# XMC1100 register map
Vendor: Infineon; File version: 1.2.2 (Reference Manual v1.2)
CPU: CM0 r0p0, little endian, no MPU, no FPU, 2 interrupt priority bits
Registers are 32-bit, read-write, reset 0x0 unless marked. A register's access mark holds for its fields unless they carry their own. Offsets are from the block's base; [hi:lo] are bit positions; {n}, {i} and the like mark numbered series.

## SCU_RESET — System Control Unit
Base 0x40010400
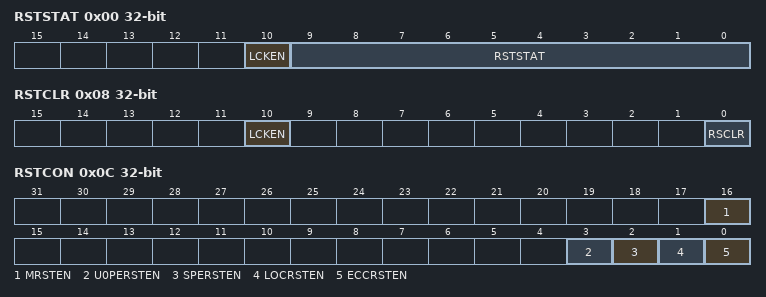
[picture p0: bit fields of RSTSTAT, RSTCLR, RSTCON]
0x00 RSTSTAT ro (reset mask 0xFFFFF000) — RCU Reset Status
  [10] LCKEN — Enable Lockup Status
    0=Reset by Lockup disabled; 1=Reset by Lockup enabled
  [9:0] RSTSTAT — Reset Status Information
0x04 RSTSET wo — RCU Reset Set Register
  [10] LCKEN — Enable Lockup Reset
    0=no effect; 1=Enable reset when Lockup gets asserted
0x08 RSTCLR wo — RCU Reset Clear Register
  [10] LCKEN — Enable Lockup Reset
    0=no effect; 1=Disable reset when Lockup gets asserted
  [0] RSCLR — Clear Reset Status
    0=no effect; 1=Clears field RSTSTAT.RSTSTAT
0x0C RSTCON access per field — RCU Reset Control Register
  [16] MRSTEN wo — Enable Master Reset
    0=No effect; 1=Triggered Master reset
  [3] U0PERSTEN rw — Enable USIC0 SRAM Parity Error Reset
    0=No reset when USIC0 memory parity error occur; 1=Reset when USIC0 memory parity error occur
  [2] SPERSTEN rw — Enable 16kbytes SRAM Parity Error Reset
    0=No reset when SRAM parity error occur; 1=Reset when SRAM parity error occur
  [1] LOCRSTEN rw — Enable Loss of Clock Reset
    0=No reset when loss of clock occur; 1=Reset when loss of clock occur
  [0] ECCRSTEN rw — Enable ECC Error Reset
    0=No reset when ECC double bit error occur; 1=Reset when ECC double bit error occur

## SCU_ANALOG — System Control Unit
Base 0x40011000
0x24 ANATSECTRL 16-bit — Temperature Sensor Control Register
  [0] TSE_EN — Temperature sensor enable
    0=Temperature sensor is disabled; 1=Temperature sensor is switched on
0x30 ANATSEIH 16-bit — Temperature Sensor High Temperature Interrupt Register
  [15:0] TSE_IH — Counter value for high temperature interrupt
0x34 ANATSEIL 16-bit reset 0xFFFF — Temperature Sensor Low Temperature Interrupt Register
  [15:0] TSE_IL — Counter value for low temperature interrupt
0x40 ANATSEMON 16-bit ro — Temperature Sensor Counter2 Monitor Register
  [15:0] TSE_MON — Monitor Counter2 value; loaded by TSE_DONE
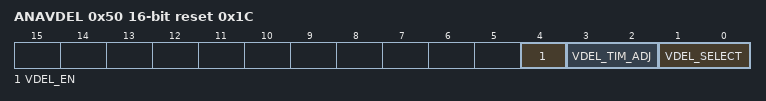
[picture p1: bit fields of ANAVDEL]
0x50 ANAVDEL 16-bit reset 0x1C — Voltage Detector Control Register
  [4] VDEL_EN — VDEL unit Enable
    0=VDEL is disabled; 1=VDEL is active
  [3:2] VDEL_TIM_ADJ — VDEL Timing Setting
    0=typ 1us - slowest response time; 1=typ 500n; 2=typ 250n; 3=no delay - fastest response time
  [1:0] VDEL_SELECT — VDEL Range Select
    0=2.25V; 1=3.0V; 2=4.4V
0x6C ANAOFFSET 16-bit reset 0x4 — DCO1 Offset Register
  [3:0] ADJL_OFFSET
    0=- 3.75%, typ; 1=- 2.85%, typ; 4=0, default; 5=+ 0.95%, typ; 8=+ 3.75%, typ

## CCU40 — Capture Compare Unit 4 - Unit 0
Base 0x48040000
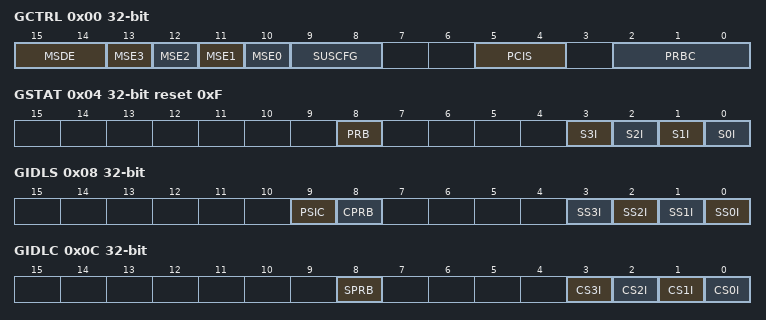
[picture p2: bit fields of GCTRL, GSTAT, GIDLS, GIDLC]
0x00 GCTRL — Global Control Register
  [15:14] MSDE — Multi Channel shadow transfer request configuration
    0=Only the shadow transfer for period and compare values is requested; 1=Shadow transfer for the compare, period and prescaler compare values is requested; 3=Shadow transfer for the compare, period, prescaler and dither compare values is requested
  [n+10] MSE{n} (n=0..3) — Slice {n} Multi Channel shadow transfer enable
    0=Shadow transfer can only be requested by SW; 1=Shadow transfer can be requested via SW and via the CCU4x.MCSS input
  [9:8] SUSCFG — Suspend Mode Configuration
    0=Suspend request ignored. The module never enters in suspend; 1=Stops all the running slices immediately. Safe stop is not applied.; 2=Stops the block immediately and clamps all the outputs to PASSIVE state. Safe stop is applied.; 3=Waits for the roll over of each slice to stop and clamp the slices outputs. Safe stop is applied.
  [5:4] PCIS — Prescaler Input Clock Selection
    0=Module clock; 1=CCU4x.ECLKA; 2=CCU4x.ECLKB; 3=CCU4x.ECLKC
  [2:0] PRBC — Prescaler Clear Configuration
    0=SW only; {v}=GSTATThe register contains the status of the prescaler and each timer slice (idle mode or running)..PRB and prescaler registers are cleared when the Run Bit of CC{v+39} is cleared (v=1..4)
0x04 GSTAT ro reset 0xF — Global Status Register
  [8] PRB — Prescaler Run Bit
    0=Prescaler is stopped; 1=Prescaler is running
  [n] S{n}I (n=0..3) — CC{n+40} IDLE status
    0=Running; 1=Idle
0x08 GIDLS wo — Global Idle Set
  [9] PSIC — Prescaler clear
  [8] CPRB — Prescaler Run Bit Clear
  [n] SS{n}I (n=0..3) — CC{n+40} IDLE mode set
0x0C GIDLC wo — Global Idle Clear
  [8] SPRB — Prescaler Run Bit Set
  [n] CS{n}I (n=0..3) — CC{n+40} IDLE mode clear
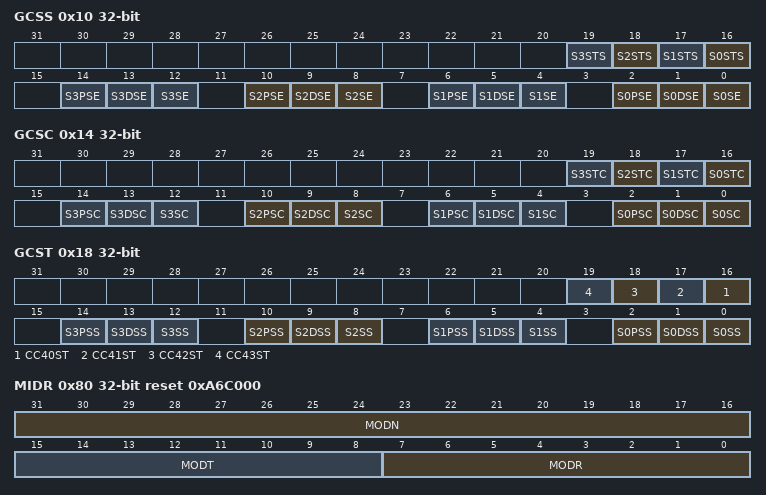
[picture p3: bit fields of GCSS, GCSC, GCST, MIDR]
0x10 GCSS wo — Global Channel Set
  [n+16] S{n}STS (n=0..3) — Slice {n} status bit set
  [4n+2] S{n}PSE (n=0..3) — Slice {n} Prescaler shadow transfer set enable
  [4n+1] S{n}DSE (n=0..3) — Slice {n} Dither shadow transfer set enable
  [4n] S{n}SE (n=0..3) — Slice {n} shadow transfer set enable
0x14 GCSC wo — Global Channel Clear
  [n+16] S{n}STC (n=0..3) — Slice {n} status bit clear
  [4n+2] S{n}PSC (n=0..3) — Slice {n} Prescaler shadow transfer clear
  [4n+1] S{n}DSC (n=0..3) — Slice {n} Dither shadow transfer clear
  [4n] S{n}SC (n=0..3) — Slice {n} shadow transfer clear
0x18 GCST ro — Global Channel Status
  [n-24] CC{n}ST (n=40..43) — Slice {n-40} status bit
  [4n+2] S{n}PSS (n=0..3) — Slice {n} Prescaler shadow transfer status
    0=Prescaler shadow transfer has not been requested; 1=Prescaler shadow transfer has been requested
  [4n+1] S{n}DSS (n=0..3) — Slice {n} Dither shadow transfer status
    0=Dither shadow transfer has not been requested; 1=Dither shadow transfer has been requested
  [4n] S{n}SS (n=0..3) — Slice {n} shadow transfer status
    0=Shadow transfer has not been requested; 1=Shadow transfer has been requested
0x80 MIDR ro reset 0xA6C000 (reset mask 0xFFFFFF00) — Module Identification
  [31:16] MODN — Module Number
  [15:8] MODT — Module Type
  [7:0] MODR — Module Revision

## Notices in the file
Copyright (C) 2012 Infineon Technologies AG. All rights reserved.
Infineon Technologies AG (Infineon) is supplying this software for use with
Infineon's microcontrollers.  This file can be freely distributed within
development tools that are supporting such microcontrollers.
THIS SOFTWARE IS PROVIDED "AS IS".  NO WARRANTIES, WHETHER EXPRESS, IMPLIED
OR STATUTORY, INCLUDING, BUT NOT LIMITED TO, IMPLIED WARRANTIES OF
MERCHANTABILITY AND FITNESS FOR A PARTICULAR PURPOSE APPLY TO THIS SOFTWARE.
INFINEON SHALL NOT, IN ANY CIRCUMSTANCES, BE LIABLE FOR SPECIAL, INCIDENTAL,
OR CONSEQUENTIAL DAMAGES, FOR ANY REASON WHATSOEVER.
